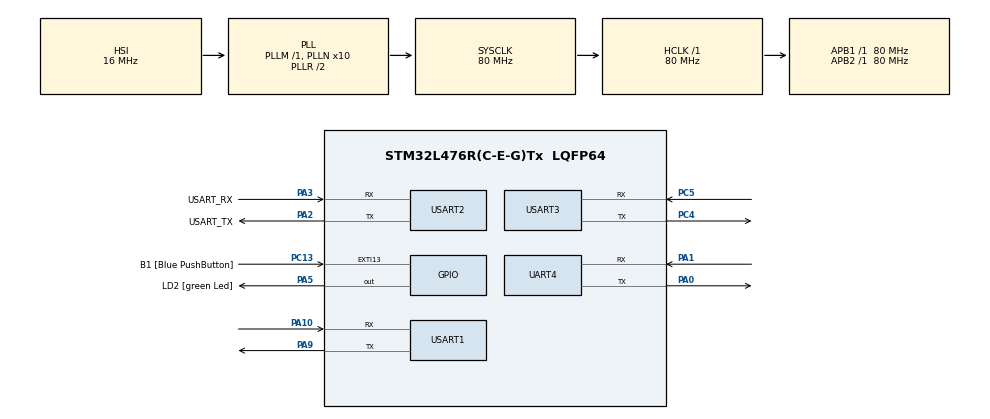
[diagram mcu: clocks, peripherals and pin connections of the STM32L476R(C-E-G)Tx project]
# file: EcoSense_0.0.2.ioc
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Mcu.Family=STM32L4
NVIC.USART3_IRQn=true\:0\:0\:false\:false\:true\:true\:true
PA2.GPIO_PuPd=GPIO_NOPULL
RCC.CortexFreq_Value=80000000
PH0-OSC_IN\ (PH0).Signal=RCC_OSC_IN
PA3.GPIO_PuPd=GPIO_NOPULL
PA2.GPIO_Speed=GPIO_SPEED_FREQ_VERY_HIGH
PC5.Mode=Asynchronous
PC13.GPIO_Label=B1 [Blue PushButton]
PA3.GPIO_Speed=GPIO_SPEED_FREQ_VERY_HIGH
RCC.SYSCLKSource=RCC_SYSCLKSOURCE_PLLCLK
ProjectManager.StackSize=0x400
PB3\ (JTDO-TRACESWO).Signal=SYS_JTDO-SWO
USART3.VirtualMode-Asynchronous=VM_ASYNC
PA14\ (JTCK-SWCLK).Signal=SYS_JTCK-SWCLK
RCC.HCLKFreq_Value=80000000
RCC.APB2TimFreq_Value=80000000
RCC.AHBFreq_Value=80000000
RCC.PREFETCH_ENABLE=1
RCC.HSE_VALUE=8000000
USART2.VirtualMode-Asynchronous=VM_ASYNC
PA5.GPIO_PuPd=GPIO_NOPULL
PA0.Mode=Asynchronous
PC13.GPIO_PuPd=GPIO_NOPULL
PA0.Signal=UART4_TX
Mcu.Package=LQFP64
PA2.GPIO_Label=USART_TX
PA10.Signal=USART1_RX
RCC.APB1TimFreq_Value=80000000
PC5.Signal=USART3_RX
PA13\ (JTMS-SWDIO).Signal=SYS_JTMS-SWDIO
NVIC.USART1_IRQn=true\:0\:0\:false\:false\:true\:true\:true
PC4.Mode=Asynchronous
PA3.Signal=USART2_RX
NVIC.UART4_IRQn=true\:0\:0\:false\:false\:true\:true\:true
PA2.GPIO_Mode=GPIO_MODE_AF_PP
RCC.MSI_VALUE=4000000
RCC.PLLSourceVirtual=RCC_PLLSOURCE_HSI
PA10.Mode=Asynchronous
PC13.Signal=GPXTI13
PC4.Signal=USART3_TX
PC15-OSC32_OUT\ (PC15).Signal=RCC_OSC32_OUT
PA14\ (JTCK-SWCLK).GPIO_Label=TCK
PB3\ (JTDO-TRACESWO).GPIO_Label=SWO
NVIC.USART2_IRQn=true\:0\:0\:false\:false\:true\:true\:true
PH1-OSC_OUT\ (PH1).Signal=RCC_OSC_OUT
USART1.VirtualMode-Asynchronous=VM_ASYNC
PA3.Mode=Asynchronous
PA9.Mode=Asynchronous
ProjectManager.TargetToolchain=STM32CubeIDE
PA3.GPIO_Mode=GPIO_MODE_AF_PP
PA9.Signal=USART1_TX
RCC.USBFreq_Value=64000000
RCC.LSE_VALUE=32768
PA1.Signal=UART4_RX
PA5.Signal=GPIO_Output
board=NUCLEO-L476RG
RCC.VCOOutputFreq_Value=160000000
RCC.APB2Freq_Value=80000000
PA1.Mode=Asynchronous
PA5.GPIO_ModeDefaultOutputPP=GPIO_MODE_OUTPUT_PP
PA13\ (JTMS-SWDIO).GPIO_Label=TMS
RCC.ADCFreq_Value=64000000
Mcu.Name=STM32L476R(C-E-G)Tx
PA2.Signal=USART2_TX
RCC.SYSCLKFreq_VALUE=80000000
PA5.GPIO_Label=LD2 [green Led]
PC13.GPIO_ModeDefaultEXTI=GPIO_MODE_IT_FALLING
PC14-OSC32_IN\ (PC14).Signal=RCC_OSC32_IN
ProjectManager.HeapSize=0x200
RCC.HSI_VALUE=16000000
PA5.GPIO_Speed=GPIO_SPEED_FREQ_LOW
NVIC.PriorityGroup=NVIC_PRIORITYGROUP_4
RCC.PLLN=10
PA2.Mode=Asynchronous
RCC.APB1Freq_Value=80000000
PA3.GPIO_Label=USART_RX

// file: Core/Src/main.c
/* USER CODE BEGIN Header */
/**
  ******************************************************************************
  * @file           : main.c
  * @brief          : Main program body
  ******************************************************************************
  * @attention
  *
  * <h2><center>&copy; Copyright (c) 2021 STMicroelectronics.
  * All rights reserved.</center></h2>
  *
  * This software component is licensed by ST under BSD 3-Clause license,
  * the "License"; You may not use this file except in compliance with the
  * License. You may obtain a copy of the License at:
  *                        opensource.org/licenses/BSD-3-Clause
  *
  ******************************************************************************
  */
/* USER CODE END Header */
#include "main.h"

/* USER CODE BEGIN Includes */
#include "uart.h"
#include "api_camera.h"
#include "api_wifi.h"
#include "round_robin.h"
/* USER CODE END Includes */

UART_HandleTypeDef huart4;
UART_HandleTypeDef huart1;
UART_HandleTypeDef huart2;
UART_HandleTypeDef huart3;

void SystemClock_Config(void);
static void MX_GPIO_Init(void);
static void MX_USART2_UART_Init(void);
static void MX_USART3_UART_Init(void);
static void MX_USART1_UART_Init(void);
static void MX_UART4_Init(void);

int main(void)
{

  /* MCU Configuration--------------------------------------------------------*/

  /* Reset of all peripherals, Initializes the Flash interface and the Systick. */
  HAL_Init();

  /* Configure the system clock */
  SystemClock_Config();

  /* Initialize all configured peripherals */
  MX_GPIO_Init();
  MX_USART2_UART_Init();
  MX_USART3_UART_Init();
  MX_USART1_UART_Init();
  MX_UART4_Init();

  /* Infinite loop */
  while (1)
  {
#if 0
	    api_ltegps_check();
		HAL_Delay(1000);
		api_ltegps_gpsconnect();
		api_ltegps_lteconnect();
		api_ltegps_lteping();
		HAL_Delay(1000);
#endif

#if 1
		api_wifi_check();
		HAL_Delay(1000);
		api_wifi_check();
		HAL_Delay(1000);
		api_wifi_check();
		HAL_Delay(1000);
		api_wifi_connect();
		HAL_Delay(1000);
		api_wifi_ping();
		__NOP();
#endif

#if 0
		api_wifi_connect();
		HAL_Delay(5000);
		api_wifi_ping();
#endif

#if 0

		api_camera_connect();
		HAL_Delay(5000);
#endif

#if 0
		switch(rrCurrentState){

		case START:

			rrCurrentState = CAMERA;

			break;

		case CAMERA:

			// camera image data get using SC03MPA module
			//api_camera_connect();
			HAL_Delay(1000);

			rrPreviousState = rrCurrentState;
			rrCurrentState = WIFI;

			break;

		case WIFI:

			// Wi-Fi ping to google.com using WE310F5-I dev kit
			api_wifi_connect();
			HAL_Delay(1000);

			rrPreviousState = rrCurrentState;
			rrCurrentState = DATA_AQ;

			break;

		case DATA_AQ:

			// retreive information from sensors
			//api_camera_connect();
			HAL_Delay(1000);
			api_wifi_ping();
			HAL_Delay(1000);
			// upload information

			// return to Wi-Fi or LTE
			rrCurrentState = rrPreviousState;

			break;

		}
#endif
  }
}

void SystemClock_Config(void)
{
  RCC_OscInitTypeDef RCC_OscInitStruct = {0};
  RCC_ClkInitTypeDef RCC_ClkInitStruct = {0};
  RCC_PeriphCLKInitTypeDef PeriphClkInit = {0};

  /** Initializes the RCC Oscillators according to the specified parameters
  * in the RCC_OscInitTypeDef structure.
  */
  RCC_OscInitStruct.OscillatorType = RCC_OSCILLATORTYPE_HSI;
  RCC_OscInitStruct.HSIState = RCC_HSI_ON;
  RCC_OscInitStruct.HSICalibrationValue = RCC_HSICALIBRATION_DEFAULT;
  RCC_OscInitStruct.PLL.PLLState = RCC_PLL_ON;
  RCC_OscInitStruct.PLL.PLLSource = RCC_PLLSOURCE_HSI;
  RCC_OscInitStruct.PLL.PLLM = 1;
  RCC_OscInitStruct.PLL.PLLN = 10;
  RCC_OscInitStruct.PLL.PLLP = RCC_PLLP_DIV7;
  RCC_OscInitStruct.PLL.PLLQ = RCC_PLLQ_DIV2;
  RCC_OscInitStruct.PLL.PLLR = RCC_PLLR_DIV2;
  if (HAL_RCC_OscConfig(&RCC_OscInitStruct) != HAL_OK)
  {
    Error_Handler();
  }
  /** Initializes the CPU, AHB and APB buses clocks
  */
  RCC_ClkInitStruct.ClockType = RCC_CLOCKTYPE_HCLK|RCC_CLOCKTYPE_SYSCLK
                              |RCC_CLOCKTYPE_PCLK1|RCC_CLOCKTYPE_PCLK2;
  RCC_ClkInitStruct.SYSCLKSource = RCC_SYSCLKSOURCE_PLLCLK;
  RCC_ClkInitStruct.AHBCLKDivider = RCC_SYSCLK_DIV1;
  RCC_ClkInitStruct.APB1CLKDivider = RCC_HCLK_DIV1;
  RCC_ClkInitStruct.APB2CLKDivider = RCC_HCLK_DIV1;

  if (HAL_RCC_ClockConfig(&RCC_ClkInitStruct, FLASH_LATENCY_4) != HAL_OK)
  {
    Error_Handler();
  }
  PeriphClkInit.PeriphClockSelection = RCC_PERIPHCLK_USART1|RCC_PERIPHCLK_USART2
                              |RCC_PERIPHCLK_USART3|RCC_PERIPHCLK_UART4;
  PeriphClkInit.Usart1ClockSelection = RCC_USART1CLKSOURCE_PCLK2;
  PeriphClkInit.Usart2ClockSelection = RCC_USART2CLKSOURCE_PCLK1;
  PeriphClkInit.Usart3ClockSelection = RCC_USART3CLKSOURCE_PCLK1;
  PeriphClkInit.Uart4ClockSelection = RCC_UART4CLKSOURCE_PCLK1;
  if (HAL_RCCEx_PeriphCLKConfig(&PeriphClkInit) != HAL_OK)
  {
    Error_Handler();
  }
  /** Configure the main internal regulator output voltage
  */
  if (HAL_PWREx_ControlVoltageScaling(PWR_REGULATOR_VOLTAGE_SCALE1) != HAL_OK)
  {
    Error_Handler();
  }
}

static void MX_UART4_Init(void)
{

  huart4.Instance = UART4;
  huart4.Init.BaudRate = 115200;
  huart4.Init.WordLength = UART_WORDLENGTH_8B;
  huart4.Init.StopBits = UART_STOPBITS_1;
  huart4.Init.Parity = UART_PARITY_NONE;
  huart4.Init.Mode = UART_MODE_TX_RX;
  huart4.Init.HwFlowCtl = UART_HWCONTROL_NONE;
  huart4.Init.OverSampling = UART_OVERSAMPLING_16;
  huart4.Init.OneBitSampling = UART_ONE_BIT_SAMPLE_DISABLE;
  huart4.AdvancedInit.AdvFeatureInit = UART_ADVFEATURE_NO_INIT;
  if (HAL_UART_Init(&huart4) != HAL_OK)
  {
    Error_Handler();
  }
  /* USER CODE BEGIN UART4_Init 2 */
  UART4->CR1 |= USART_CR1_RXNEIE; // Enable RXNE interrupt
  UART4->RQR |= USART_RQR_RXFRQ;  // Clear RXNE flag
  /* USER CODE END UART4_Init 2 */

}

static void MX_USART1_UART_Init(void)
{

  huart1.Instance = USART1;
  huart1.Init.BaudRate = 115200;
  huart1.Init.WordLength = UART_WORDLENGTH_8B;
  huart1.Init.StopBits = UART_STOPBITS_1;
  huart1.Init.Parity = UART_PARITY_NONE;
  huart1.Init.Mode = UART_MODE_TX_RX;
  huart1.Init.HwFlowCtl = UART_HWCONTROL_NONE;
  huart1.Init.OverSampling = UART_OVERSAMPLING_16;
  huart1.Init.OneBitSampling = UART_ONE_BIT_SAMPLE_DISABLE;
  huart1.AdvancedInit.AdvFeatureInit = UART_ADVFEATURE_NO_INIT;
  if (HAL_UART_Init(&huart1) != HAL_OK)
  {
    Error_Handler();
  }
  /* USER CODE BEGIN USART1_Init 2 */
  USART1->CR1 |= USART_CR1_RXNEIE; // Enable RXNE interrupt
  USART1->RQR |= USART_RQR_RXFRQ;  // Clear RXNE flag
  /* USER CODE END USART1_Init 2 */

}

static void MX_USART2_UART_Init(void)
{

  huart2.Instance = USART2;
  huart2.Init.BaudRate = 115200;
  huart2.Init.WordLength = UART_WORDLENGTH_8B;
  huart2.Init.StopBits = UART_STOPBITS_1;
  huart2.Init.Parity = UART_PARITY_NONE;
  huart2.Init.Mode = UART_MODE_TX_RX;
  huart2.Init.HwFlowCtl = UART_HWCONTROL_NONE;
  huart2.Init.OverSampling = UART_OVERSAMPLING_16;
  huart2.Init.OneBitSampling = UART_ONE_BIT_SAMPLE_DISABLE;
  huart2.AdvancedInit.AdvFeatureInit = UART_ADVFEATURE_NO_INIT;
  if (HAL_UART_Init(&huart2) != HAL_OK)
  {
    Error_Handler();
  }
  /* USER CODE BEGIN USART2_Init 2 */
  //USART2->CR1 |= USART_CR1_RXNEIE; // enable RX interrupt
  USART2->RQR |= USART_RQR_RXFRQ;  // Clear RXNE flag
  /* USER CODE END USART2_Init 2 */

}

static void MX_USART3_UART_Init(void)
{

  huart3.Instance = USART3;
  huart3.Init.BaudRate = 115200;
  huart3.Init.WordLength = UART_WORDLENGTH_8B;
  huart3.Init.StopBits = UART_STOPBITS_1;
  huart3.Init.Parity = UART_PARITY_NONE;
  huart3.Init.Mode = UART_MODE_TX_RX;
  huart3.Init.HwFlowCtl = UART_HWCONTROL_NONE;
  huart3.Init.OverSampling = UART_OVERSAMPLING_16;
  huart3.Init.OneBitSampling = UART_ONE_BIT_SAMPLE_DISABLE;
  huart3.AdvancedInit.AdvFeatureInit = UART_ADVFEATURE_NO_INIT;
  if (HAL_UART_Init(&huart3) != HAL_OK)
  {
    Error_Handler();
  }
  /* USER CODE BEGIN USART3_Init 2 */
  USART3->CR1 |= USART_CR1_RXNEIE; // enable RX interrupt
  USART3->RQR |= USART_RQR_RXFRQ;  // Clear RXNE flag
  /* USER CODE END USART3_Init 2 */

}

static void MX_GPIO_Init(void)
{
  GPIO_InitTypeDef GPIO_InitStruct = {0};

  /* GPIO Ports Clock Enable */
  __HAL_RCC_GPIOC_CLK_ENABLE();
  __HAL_RCC_GPIOH_CLK_ENABLE();
  __HAL_RCC_GPIOA_CLK_ENABLE();
  __HAL_RCC_GPIOB_CLK_ENABLE();

  /*Configure GPIO pin Output Level */
  HAL_GPIO_WritePin(LD2_GPIO_Port, LD2_Pin, GPIO_PIN_RESET);

  /*Configure GPIO pin : B1_Pin */
  GPIO_InitStruct.Pin = B1_Pin;
  GPIO_InitStruct.Mode = GPIO_MODE_IT_FALLING;
  GPIO_InitStruct.Pull = GPIO_NOPULL;
  HAL_GPIO_Init(B1_GPIO_Port, &GPIO_InitStruct);

  /*Configure GPIO pin : LD2_Pin */
  GPIO_InitStruct.Pin = LD2_Pin;
  GPIO_InitStruct.Mode = GPIO_MODE_OUTPUT_PP;
  GPIO_InitStruct.Pull = GPIO_NOPULL;
  GPIO_InitStruct.Speed = GPIO_SPEED_FREQ_LOW;
  HAL_GPIO_Init(LD2_GPIO_Port, &GPIO_InitStruct);

}

void Error_Handler(void)
{
  __disable_irq();
  while (1)
  {
  }
}

/************************ (C) COPYRIGHT STMicroelectronics *****END OF FILE****/
